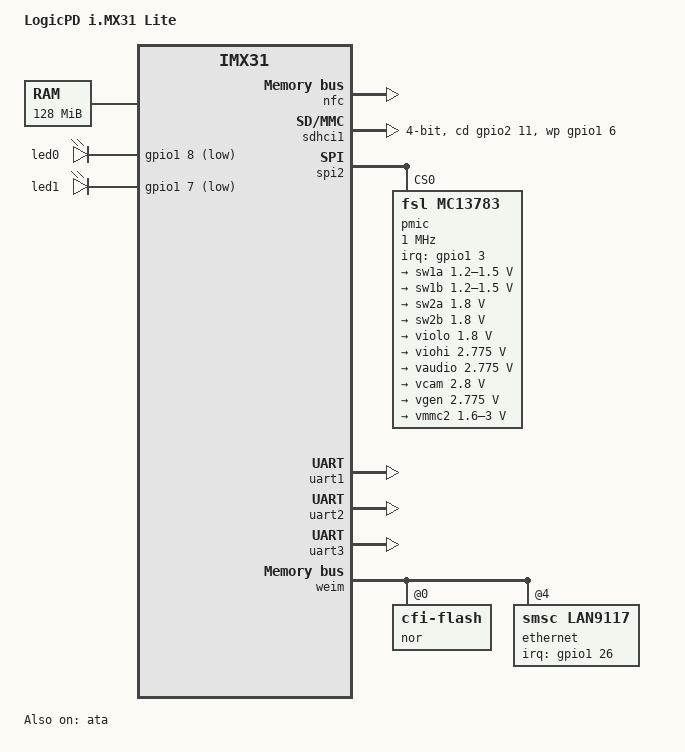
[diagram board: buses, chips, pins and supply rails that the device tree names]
/dts-v1/;
#include "imx31.dtsi"
#include <dt-bindings/gpio/gpio.h>
#include <dt-bindings/interrupt-controller/irq.h>
/ {
	model = "LogicPD i.MX31 Lite";
	compatible = "logicpd,imx31-lite", "fsl,imx31";
	chosen {
		stdout-path = &uart1;
	};
	memory@80000000 {
		device_type = "memory";
		reg = <0x80000000 0x8000000>;
	};
	leds {
		compatible = "gpio-leds";
		led0 {
			gpios = <&gpio1 8 GPIO_ACTIVE_LOW>;
		};
		led1 {
			gpios = <&gpio1 7 GPIO_ACTIVE_LOW>;
		};
	};
};
&ata {
	status = "okay";
};
&nfc {
	nand-bus-width = <8>;
	nand-ecc-mode = "hw";
	nand-on-flash-bbt;
	status = "okay";
};
&sdhci1 {
	bus-width = <4>;
	cd-gpios = <&gpio2 11 GPIO_ACTIVE_HIGH>;
	wp-gpios = <&gpio1 6 GPIO_ACTIVE_HIGH>;
	status = "okay";
};
&spi2 {
	status = "okay";
	pmic@0 {
		compatible = "fsl,mc13783";
		reg = <0>;
		spi-cs-high;
		spi-max-frequency = <1000000>;
		interrupt-parent = <&gpio1>;
		interrupts = <3 IRQ_TYPE_EDGE_RISING>;
		fsl,mc13xxx-uses-adc;
		fsl,mc13xxx-uses-rtc;
		regulators {
			sw1a {		 
				regulator-min-microvolt = <1200000>;
				regulator-max-microvolt = <1500000>;
				regulator-always-on;
				regulator-boot-on;
			};
			sw1b {		 
				regulator-min-microvolt = <1200000>;
				regulator-max-microvolt = <1500000>;
				regulator-always-on;
				regulator-boot-on;
			};
			sw2a {		 
				regulator-min-microvolt = <1800000>;
				regulator-max-microvolt = <1800000>;
				regulator-always-on;
				regulator-boot-on;
			};
			sw2b {		 
				regulator-min-microvolt = <1800000>;
				regulator-max-microvolt = <1800000>;
				regulator-always-on;
				regulator-boot-on;
			};
			violo {		 
				regulator-min-microvolt = <1800000>;
				regulator-max-microvolt = <1800000>;
				regulator-always-on;
				regulator-boot-on;
			};
			viohi {		 
				regulator-min-microvolt = <2775000>;
				regulator-max-microvolt = <2775000>;
				regulator-always-on;
				regulator-boot-on;
			};
			vaudio {	 
				regulator-min-microvolt = <2775000>;
				regulator-max-microvolt = <2775000>;
			};
			vcam {		 
				regulator-min-microvolt = <2800000>;
				regulator-max-microvolt = <2800000>;
			};
			vgen {		 
				regulator-min-microvolt = <2775000>;
				regulator-max-microvolt = <2775000>;
				regulator-always-on;
				regulator-boot-on;
			};
			vmmc2 {		 
				regulator-min-microvolt = <1600000>;
				regulator-max-microvolt = <3000000>;
				regulator-always-on;
				regulator-boot-on;
			};
		};
	};
};
&uart1 {
	uart-has-rtscts;
	status = "okay";
};
&uart2 {
	uart-has-rtscts;
	status = "okay";
};
&uart3 {
	uart-has-rtscts;
	status = "okay";
};
&weim {
	status = "okay";
	nor@0,0 {
		compatible = "cfi-flash";
		reg = <0 0x0 0x200000>;
		bank-width = <2>;
		linux,mtd-name = "physmap-flash.0";
		fsl,weim-cs-timing = <0x0000cf03 0xa0330d01 0x00220800>;
	};
	ethernet@4,0 {
		compatible = "smsc,lan9117", "smsc,lan9115";
		reg = <4 0x0 0x100>;
		interrupt-parent = <&gpio1>;
		interrupts = <26 IRQ_TYPE_EDGE_FALLING>;
		phy-mode = "mii";
		reg-io-width = <2>;
		smsc,irq-push-pull;
		fsl,weim-cs-timing = <0x00008701 0x04000541 0x00010000>;
	};
};
